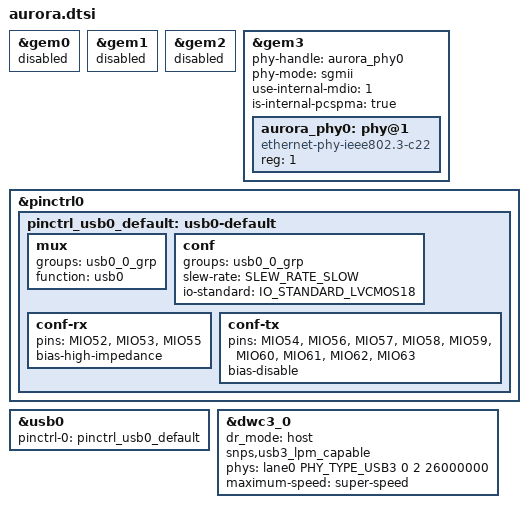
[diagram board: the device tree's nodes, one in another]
#include <dt-bindings/input/input.h>
#include <dt-bindings/gpio/gpio.h>
#include <dt-bindings/pinctrl/pinctrl-zynqmp.h>
#include <dt-bindings/phy/phy.h>

&gem0 {
    status = "disabled";
};

&gem1 {
    status = "disabled";
};

&gem2 {
    status = "disabled";
};

// TODO: move to Aurora carrier DT Overlay
&gem3 {
    status = "okay";
    phy-handle = <&aurora_phy0>;
    phy-mode = "sgmii";
    use-internal-mdio = <1>;
    is-internal-pcspma = "true";
    
    aurora_phy0: phy@1 {
        reg = <1>;
        compatible = "ethernet-phy-ieee802.3-c22";
        device_type = "ethernet-phy";
    };

};

&pinctrl0 {
	status = "okay";
	pinctrl_usb0_default: usb0-default {
		mux {
			groups = "usb0_0_grp";
			function = "usb0";
		};

		conf {
			groups = "usb0_0_grp";
			slew-rate = <SLEW_RATE_SLOW>;
			io-standard = <IO_STANDARD_LVCMOS18>;
		};

		conf-rx {
			pins = "MIO52", "MIO53", "MIO55";
			bias-high-impedance;
		};

		conf-tx {
			pins = "MIO54", "MIO56", "MIO57", "MIO58", "MIO59",
			       "MIO60", "MIO61", "MIO62", "MIO63";
			bias-disable;
		};
	};
};

&usb0 {
	status = "okay";
	pinctrl-names = "default";
	pinctrl-0 = <&pinctrl_usb0_default>;
};

&dwc3_0 {
	status = "okay";
	dr_mode = "host";
	snps,usb3_lpm_capable;
	phy-names = "usb3-phy";
	phys = <&lane0 PHY_TYPE_USB3 0 2 26000000>;
	maximum-speed = "super-speed";
};
